VERSION ""

NS_ :

BS_:

BU_: Bosch_LWS Controls
VAL_TABLE_ LWS_Config 3 "Sets the signal LWS_Angle to 0Â°" 5 "Resets calibration status" ;
VAL_TABLE_ LWS_TrimmingStatus 0 "FAULT - Sensor Not Trimmed" 1 "Sensor Trimmed" ;
VAL_TABLE_ LWS_Fault 0 "OK" 1 "Internal Fault" ;
VAL_TABLE_ LWS_CalibrationStatus 0 "Sensor Not Calibrated" 1 "Sensor Calibrated" ;

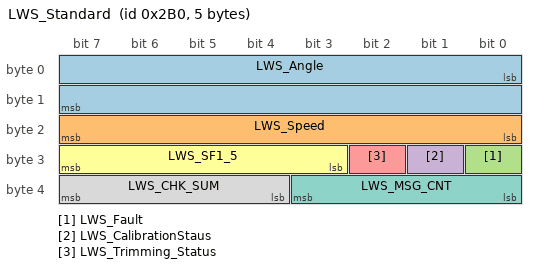
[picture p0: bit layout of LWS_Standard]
BO_ 688 LWS_Standard: 5 Bosch_LWS
 SG_ LWS_Angle : 0|16@1- (0.1,0) [-780|780] "Â°" Vector__XXX
 SG_ LWS_Speed : 16|8@1+ (4,0) [0|1016] "Â°/s" Vector__XXX
 SG_ LWS_Fault : 24|1@1+ (1,0) [0|1] "" Vector__XXX
 SG_ LWS_CalibrationStaus : 25|1@1+ (1,0) [0|1] "" Vector__XXX
 SG_ LWS_Trimming_Status : 26|1@1+ (1,0) [0|1] "" Vector__XXX
 SG_ LWS_SF1_5 : 27|5@1+ (1,0) [0|31] "" Vector__XXX
 SG_ LWS_MSG_CNT : 32|4@1+ (1,0) [0|15] "" Vector__XXX
 SG_ LWS_CHK_SUM : 36|4@1+ (1,0) [0|15] "" Vector__XXX

BO_ 1984 LWS_Config: 2 Controls
 SG_ LWS_CCW : 0|4@1+ (1,0) [0|15] "" Vector__XXX
 SG_ LWS_RES : 4|12@1+ (1,0) [0|4095] "" Vector__XXX

BA_DEF_  "DBName" STRING ;
BA_DEF_ BO_  "GenMsgSendType" ENUM  "Cyclic","Event","CyclicAndEvent","CyclicAndEventNoRepetition","None","Spontaneous";
BA_DEF_ BO_  "VFrameFormat" ENUM  "StandardCAN","ExtendedCAN","reserved","J1939PG","reserved","reserved","reserved","reserved","reserved","reserved","reserved","reserved","reserved","reserved","StandardCAN_FD","ExtendedCAN_FD";
BA_DEF_  "BusType" STRING ;
BA_DEF_DEF_  "DBName" "";
BA_DEF_DEF_  "GenMsgSendType" "Cyclic";
BA_DEF_DEF_  "VFrameFormat" "StandardCAN";
BA_DEF_DEF_  "BusType" "";
BA_ "BusType" "CAN";
BA_ "DBName" "SteeringCAN";
VAL_ 688 LWS_Fault 0 "OK" 1 "Internal Fault" ;
VAL_ 688 LWS_CalibrationStaus 0 "Sensor Not Calibrated" 1 "Sensor Calibrated" ;
VAL_ 688 LWS_Trimming_Status 0 "FAULT - Sensor Not Trimmed" 1 "Sensor Trimmed" ;
VAL_ 1984 LWS_CCW 3 "Sets the signal LWS_Angle to 0Â°" 5 "Resets calibration status" ;
